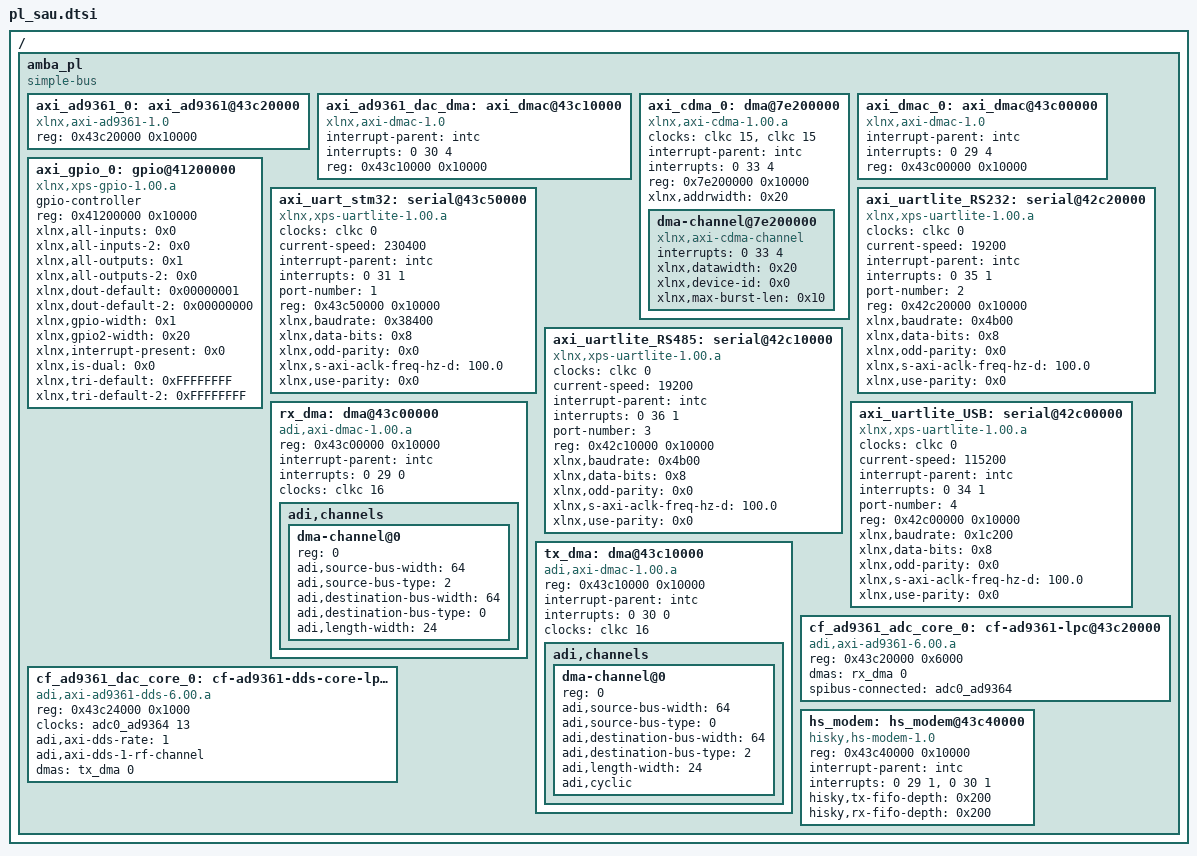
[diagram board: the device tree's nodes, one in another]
/*
 * CAUTION: This file is automatically generated by Xilinx.
 * Version:  
 * Today is: Wed Jan 15 12:55:47 2020
 */

/include/ "pcw.dtsi"

/ {
	amba_pl: amba_pl {
		#address-cells = <1>;
		#size-cells = <1>;
		compatible = "simple-bus";
		ranges ;

		axi_ad9361_0: axi_ad9361@43c20000 {
			compatible = "xlnx,axi-ad9361-1.0";
			reg = <0x43c20000 0x10000>;
		};
		axi_ad9361_dac_dma: axi_dmac@43c10000 {
			compatible = "xlnx,axi-dmac-1.0";
			interrupt-parent = <&intc>;
			interrupts = <0 30 4>;
			reg = <0x43c10000 0x10000>;
		};
		axi_cdma_0: dma@7e200000 {
			#dma-cells = <1>;
			clock-names = "s_axi_lite_aclk", "m_axi_aclk";
			clocks = <&clkc 15>, <&clkc 15>;
			compatible = "xlnx,axi-cdma-1.00.a";
			interrupt-parent = <&intc>;
			interrupts = <0 33 4>;
			reg = <0x7e200000 0x10000>;
			xlnx,addrwidth = <0x20>;
			dma-channel@7e200000 {
				compatible = "xlnx,axi-cdma-channel";
				interrupts = <0 33 4>;
				xlnx,datawidth = <0x20>;
				xlnx,device-id = <0x0>;
				xlnx,max-burst-len = <0x10>;
			};
		};
		axi_dmac_0: axi_dmac@43c00000 {
			compatible = "xlnx,axi-dmac-1.0";
			interrupt-parent = <&intc>;
			interrupts = <0 29 4>;
			reg = <0x43c00000 0x10000>;
		};
		axi_gpio_0: gpio@41200000 {
			#gpio-cells = <2>;
			compatible = "xlnx,xps-gpio-1.00.a";
			gpio-controller ;
			reg = <0x41200000 0x10000>;
			xlnx,all-inputs = <0x0>;
			xlnx,all-inputs-2 = <0x0>;
			xlnx,all-outputs = <0x1>;
			xlnx,all-outputs-2 = <0x0>;
			xlnx,dout-default = <0x00000001>;
			xlnx,dout-default-2 = <0x00000000>;
			xlnx,gpio-width = <0x1>;
			xlnx,gpio2-width = <0x20>;
			xlnx,interrupt-present = <0x0>;
			xlnx,is-dual = <0x0>;
			xlnx,tri-default = <0xFFFFFFFF>;
			xlnx,tri-default-2 = <0xFFFFFFFF>;
		};
		axi_uart_stm32: serial@43c50000 {
			clock-names = "ref_clk";
			clocks = <&clkc 0>;
			compatible = "xlnx,xps-uartlite-1.00.a";
			current-speed = <230400>;
			device_type = "serial";
			interrupt-parent = <&intc>;
			interrupts = <0 31 1>;
			port-number = <1>;
			reg = <0x43c50000 0x10000>;
			xlnx,baudrate = <0x38400>;
			xlnx,data-bits = <0x8>;
			xlnx,odd-parity = <0x0>;
			xlnx,s-axi-aclk-freq-hz-d = "100.0";
			xlnx,use-parity = <0x0>;
		};
		axi_uartlite_RS232: serial@42c20000 {
			clock-names = "ref_clk";
			clocks = <&clkc 0>;
			compatible = "xlnx,xps-uartlite-1.00.a";
			current-speed = <19200>;
			device_type = "serial";
			interrupt-parent = <&intc>;
			interrupts = <0 35 1>;
			port-number = <2>;
			reg = <0x42c20000 0x10000>;
			xlnx,baudrate = <0x4b00>;
			xlnx,data-bits = <0x8>;
			xlnx,odd-parity = <0x0>;
			xlnx,s-axi-aclk-freq-hz-d = "100.0";
			xlnx,use-parity = <0x0>;
		};
		axi_uartlite_RS485: serial@42c10000 {
			clock-names = "ref_clk";
			clocks = <&clkc 0>;
			compatible = "xlnx,xps-uartlite-1.00.a";
			current-speed = <19200>;
			device_type = "serial";
			interrupt-parent = <&intc>;
			interrupts = <0 36 1>;
			port-number = <3>;
			reg = <0x42c10000 0x10000>;
			xlnx,baudrate = <0x4b00>;
			xlnx,data-bits = <0x8>;
			xlnx,odd-parity = <0x0>;
			xlnx,s-axi-aclk-freq-hz-d = "100.0";
			xlnx,use-parity = <0x0>;
		};
		axi_uartlite_USB: serial@42c00000 {
			clock-names = "ref_clk";
			clocks = <&clkc 0>;
			compatible = "xlnx,xps-uartlite-1.00.a";
			current-speed = <115200>;
			device_type = "serial";
			interrupt-parent = <&intc>;
			interrupts = <0 34 1>;
			port-number = <4>;
			reg = <0x42c00000 0x10000>;
			xlnx,baudrate = <0x1c200>;
			xlnx,data-bits = <0x8>;
			xlnx,odd-parity = <0x0>;
			xlnx,s-axi-aclk-freq-hz-d = "100.0";
			xlnx,use-parity = <0x0>;
		};

		rx_dma: dma@43c00000 {
			compatible = "adi,axi-dmac-1.00.a";
			reg = <0x43c00000 0x10000>;
			#dma-cells = <1>;
			interrupt-parent = <&intc>;
			interrupts = <0 29 0>;
			clocks = <&clkc 16>;

			adi,channels {
				#size-cells = <0>;
				#address-cells = <1>;

				dma-channel@0 {
					reg = <0>;
					adi,source-bus-width = <64>;
					adi,source-bus-type = <2>;
					adi,destination-bus-width = <64>;
					adi,destination-bus-type = <0>;
					adi,length-width = <24>;
				};
			};
		};

		tx_dma: dma@43c10000 {
			compatible = "adi,axi-dmac-1.00.a";
			reg = <0x43c10000 0x10000>;
			#dma-cells = <1>;
			interrupt-parent = <&intc>;
			interrupts = <0 30 0>;
			clocks = <&clkc 16>;

			adi,channels {
				#size-cells = <0>;
				#address-cells = <1>;

				dma-channel@0 {
					reg = <0>;
					adi,source-bus-width = <64>;
					adi,source-bus-type = <0>;
					adi,destination-bus-width = <64>;
					adi,destination-bus-type = <2>;
					adi,length-width = <24>;
					adi,cyclic;
				};
			};
		};

		cf_ad9361_adc_core_0: cf-ad9361-lpc@43c20000 {
			compatible = "adi,axi-ad9361-6.00.a";
			reg = <0x43c20000 0x6000>;
			dmas = <&rx_dma 0>;
			dma-names = "rx";

			spibus-connected = <&adc0_ad9364>;
		};

		cf_ad9361_dac_core_0: cf-ad9361-dds-core-lpc@43c24000 {
			compatible = "adi,axi-ad9361-dds-6.00.a";
			reg = <0x43c24000 0x1000>;
			clocks = <&adc0_ad9364 13>;
			clock-names = "sampl_clk";
			adi,axi-dds-rate = <1>; /* use 1 for 1RX1TX mode */
			adi,axi-dds-1-rf-channel;
			dmas = <&tx_dma 0>;
			dma-names = "tx";
		};

		hs_modem: hs_modem@43c40000 {
			#interrupt-cells = <2>;
			compatible = "hisky,hs-modem-1.0";
			reg = <0x43c40000 0x10000>;
			
			interrupt-parent = <&intc>;
			//              Rx        Tx
			interrupts = <0 29 1>, <0 30 1>;
			hisky,tx-fifo-depth = <0x200>;
			hisky,rx-fifo-depth = <0x200>;
		};
	
	};
};

